AUTOSAR XML (schema 314)
package /ComponentType
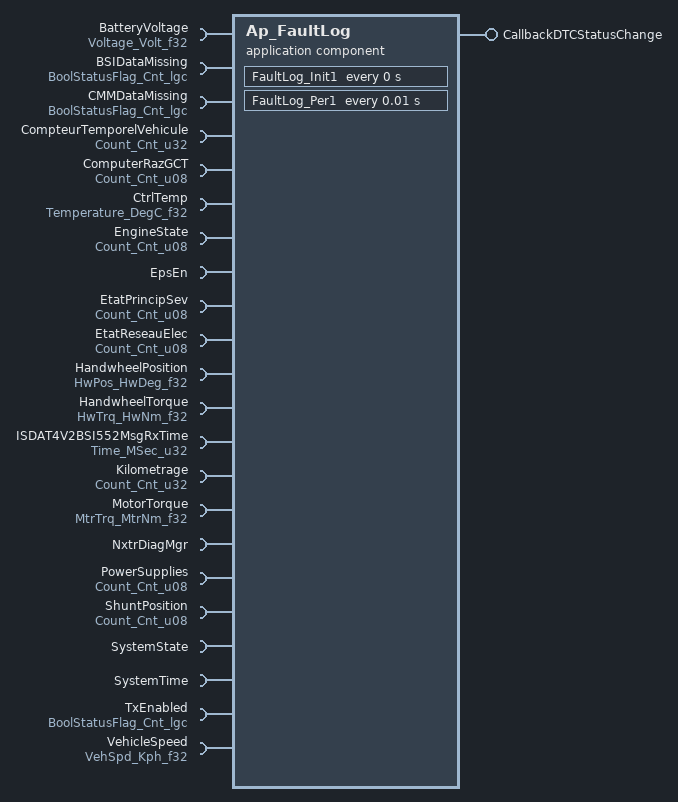
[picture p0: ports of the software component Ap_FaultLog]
  application software component type Ap_FaultLog
    provide port CallbackDTCStatusChange: server-com-spec{operation=DTCStatusChanged, queue-length=1}, provided-interface=CallbackDTCStatusChange
    22 x require port:
      BatteryVoltage: unqueued-receiver-com-spec{data-element=Volt_f32, init-value=D_ZERO_ULS_F32}, required-interface=Voltage_Volt_f32
      BSIDataMissing: unqueued-receiver-com-spec{data-element=Cnt_lgc, init-value=D_TRUE_CNT_LGC}, required-interface=BoolStatusFlag_Cnt_lgc
      CMMDataMissing: unqueued-receiver-com-spec{data-element=Cnt_lgc, init-value=D_TRUE_CNT_LGC}, required-interface=BoolStatusFlag_Cnt_lgc
      CompteurTemporelVehicule: unqueued-receiver-com-spec{data-element=Cnt_u32, init-value=D_ZERO_CNT_U32}, required-interface=Count_Cnt_u32
      ComputerRazGCT: unqueued-receiver-com-spec{data-element=Cnt_u08, init-value=D_ZERO_CNT_U8}, required-interface=Count_Cnt_u08
      CtrlTemp: unqueued-receiver-com-spec{data-element=DegC_f32, init-value=D_ZERO_ULS_F32}, required-interface=Temperature_DegC_f32
      EngineState: unqueued-receiver-com-spec{data-element=Cnt_u08, init-value=D_ZERO_CNT_U8}, required-interface=Count_Cnt_u08
      EpsEn: client-com-spec=OP_GET, required-interface=EpsEn
      EtatPrincipSev: unqueued-receiver-com-spec{data-element=Cnt_u08, init-value=D_ZERO_CNT_U8}, required-interface=Count_Cnt_u08
      EtatReseauElec: unqueued-receiver-com-spec{data-element=Cnt_u08, init-value=D_ZERO_CNT_U8}, required-interface=Count_Cnt_u08
      HandwheelPosition: unqueued-receiver-com-spec{data-element=HwDeg_f32, init-value=D_ZERO_ULS_F32}, required-interface=HwPos_HwDeg_f32
      HandwheelTorque: unqueued-receiver-com-spec{data-element=HwNm_f32, init-value=D_ZERO_ULS_F32}, required-interface=HwTrq_HwNm_f32
      ISDAT4V2BSI552MsgRxTime: unqueued-receiver-com-spec{data-element=MSec_u32, init-value=D_ZERO_CNT_U32}, required-interface=Time_MSec_u32
      Kilometrage: unqueued-receiver-com-spec{data-element=Cnt_u32, init-value=D_ZERO_CNT_U32}, required-interface=Count_Cnt_u32
      MotorTorque: unqueued-receiver-com-spec{data-element=MtrNm_f32, init-value=D_ZERO_ULS_F32}, required-interface=MtrTrq_MtrNm_f32
      NxtrDiagMgr: required-com-specs=[GetNTCActive, GetNTCFailed, GetNTCStatus, SetNTCStatus], required-interface=NxtrDiagMgr
      PowerSupplies: unqueued-receiver-com-spec{data-element=Cnt_u08, init-value=D_ZERO_CNT_U8}, required-interface=Count_Cnt_u08
      ShuntPosition: unqueued-receiver-com-spec{data-element=Cnt_u08, init-value=D_ZERO_CNT_U8}, required-interface=Count_Cnt_u08
      SystemState: required-interface=SystemState
      SystemTime: required-interface=SystemTime
        required-com-specs:
          DtrmnElapsedTime_mS_u16
          DtrmnElapsedTime_mS_u32
          DtrmnElapsedTime_uS_u16
          DtrmnElapsedTime_uS_u32
          GetSystemTime_mS_u32
          GetSystemTime_uS_u32
      TxEnabled: unqueued-receiver-com-spec{data-element=Cnt_lgc, init-value=D_FALSE_CNT_LGC}, required-interface=BoolStatusFlag_Cnt_lgc
      VehicleSpeed: unqueued-receiver-com-spec{data-element=Kph_f32, init-value=D_ZERO_ULS_F32}, required-interface=VehSpd_Kph_f32
  internal behavior Ap_FaultLog_InternalBehavior: component=Ap_FaultLog
    operation invoked event OIT_FaultLog_DTCStatusChanged_CallbackDTCStatusChange_DTCStatusChanged: start-on-event=FaultLog_DTCStatusChanged, operation=CallbackDTCStatusChange.DTCStatusChanged
    timing event FaultLog_Init1_InitEvent: start-on-event=FaultLog_Init1, period=0
    timing event TMT_FaultLog_Per1: mode-dependency=dependent-on-mode=SystemState.Mode.OFF, start-on-event=FaultLog_Per1, period=0.01
    mode switch event MST_FaultLog_Trns1_0: start-on-event=FaultLog_Trns1, activation=ENTRY, mode=SystemState.Mode.OFF
    per instance memory FaultLog: type=FaultLogType, type-definition=/DataType/FaultLogType
    port-api-options:
      enable-take-address=false, indirect-api=false, port=BatteryVoltage
      enable-take-address=false, indirect-api=false, port=BSIDataMissing
      enable-take-address=false, indirect-api=false, port=CallbackDTCStatusChange
      enable-take-address=false, indirect-api=false, port=CMMDataMissing
      enable-take-address=false, indirect-api=false, port=CompteurTemporelVehicule
      enable-take-address=false, indirect-api=false, port=ComputerRazGCT
      enable-take-address=false, indirect-api=false, port=CtrlTemp
      enable-take-address=false, indirect-api=false, port=EngineState
      enable-take-address=false, indirect-api=false, port=EpsEn
      enable-take-address=false, indirect-api=false, port=EtatPrincipSev
      enable-take-address=false, indirect-api=false, port=EtatReseauElec
      enable-take-address=false, indirect-api=false, port=HandwheelPosition
      enable-take-address=false, indirect-api=false, port=HandwheelTorque
      enable-take-address=false, indirect-api=false, port=ISDAT4V2BSI552MsgRxTime
      enable-take-address=false, indirect-api=false, port=Kilometrage
      enable-take-address=false, indirect-api=false, port=MotorTorque
      enable-take-address=false, indirect-api=false, port=NxtrDiagMgr
      enable-take-address=false, indirect-api=false, port=PowerSupplies
      enable-take-address=false, indirect-api=false, port=ShuntPosition
      enable-take-address=false, indirect-api=false, port=SystemState
      enable-take-address=false, indirect-api=false, port=SystemTime
      enable-take-address=false, indirect-api=false, port=TxEnabled
      enable-take-address=false, indirect-api=false, port=VehicleSpeed
    4 x runnable:
      FaultLog_DTCStatusChanged
        14 x data receive point:
          REC_BatteryVoltage_Volt_f32: data-element=BatteryVoltage.Volt_f32
          REC_BSIDataMissing_Cnt_lgc: data-element=BSIDataMissing.Cnt_lgc
          REC_CMMDataMissing_Cnt_lgc: data-element=CMMDataMissing.Cnt_lgc
          REC_CtrlTemp_DegC_f32: data-element=CtrlTemp.DegC_f32
          REC_EngineState_Cnt_u08: data-element=EngineState.Cnt_u08
          REC_EtatPrincipSev_Cnt_u08: data-element=EtatPrincipSev.Cnt_u08
          REC_EtatReseauElec_Cnt_u08: data-element=EtatReseauElec.Cnt_u08
          REC_HandwheelPosition_HwDeg_f32: data-element=HandwheelPosition.HwDeg_f32
          REC_HandwheelTorque_HwNm_f32: data-element=HandwheelTorque.HwNm_f32
          REC_Kilometrage_Cnt_u32: data-element=Kilometrage.Cnt_u32
          REC_MotorTorque_MtrNm_f32: data-element=MotorTorque.MtrNm_f32
          REC_PowerSupplies_Cnt_u08: data-element=PowerSupplies.Cnt_u08
          REC_ShuntPosition_Cnt_u08: data-element=ShuntPosition.Cnt_u08
          REC_VehicleSpeed_Kph_f32: data-element=VehicleSpeed.Kph_f32
        sync call SC_EpsEn_OP_GET: operation=EpsEn.OP_GET, timeout=0
        sync call SC_NxtrDiagMgr_GetNTCFailed: operation=NxtrDiagMgr.GetNTCFailed, timeout=0
      FaultLog_Init1
      FaultLog_Per1
        4 x data read access:
          READ_CompteurTemporelVehicule_Cnt_u32: data-element=CompteurTemporelVehicule.Cnt_u32
          READ_ComputerRazGCT_Cnt_u08: data-element=ComputerRazGCT.Cnt_u08
          READ_ISDAT4V2BSI552MsgRxTime_MSec_u32: data-element=ISDAT4V2BSI552MsgRxTime.MSec_u32
          READ_TxEnabled_Cnt_lgc: data-element=TxEnabled.Cnt_lgc
        sync call SC_SystemTime_GetSystemTime_mS_u32: operation=SystemTime.GetSystemTime_mS_u32, timeout=0
      FaultLog_Trns1
    service-needss:
      swc nv block needs FaultLogData: n-data-sets=0, readonly=false, reliability=LOW, resistant-to-changed-sw=false, restore-at-start=false, write-only-once=false, writing-frequency=0, writing-priority=LOW, mirror-block=FaultLog
  swc implementation Ap_FaultLog_Implementation: behavior=Ap_FaultLog_InternalBehavior
    code-descriptors:
      code Code: type=SRC
